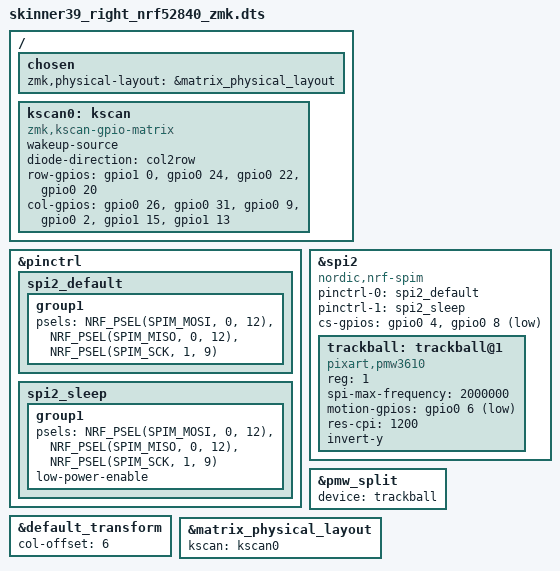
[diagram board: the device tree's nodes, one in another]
#include "skinner39.dtsi"
#include <dt-bindings/led/led.h>
#include <zephyr/dt-bindings/input/input-event-codes.h>

&pinctrl {
    spi2_default: spi2_default {
		group1 {
				psels = <NRF_PSEL(SPIM_MOSI, 0, 12)>,
				<NRF_PSEL(SPIM_MISO, 0, 12)>,
				<NRF_PSEL(SPIM_SCK, 1, 9)>;
		};
	};

    spi2_sleep: spi2_sleep {
		group1 {
				psels = <NRF_PSEL(SPIM_MOSI, 0, 12)>,
				<NRF_PSEL(SPIM_MISO, 0, 12)>,
				<NRF_PSEL(SPIM_SCK, 1, 9)>;
				low-power-enable;
		};
	};
};

nice_view_spi: &spi2 {
    compatible = "nordic,nrf-spim";
    pinctrl-0 = <&spi2_default>;
    pinctrl-1 = <&spi2_sleep>;
    pinctrl-names = "default", "sleep";
    cs-gpios = <&gpio0 4 (GPIO_ACTIVE_HIGH | GPIO_PULL_DOWN) >,
			<&gpio0 8 GPIO_ACTIVE_LOW>;
	trackball: trackball@1 {
		status = "okay";
		compatible = "pixart,pmw3610";
		reg = <1>;
		spi-max-frequency = <2000000>;
		motion-gpios = <&gpio0 6 (GPIO_ACTIVE_LOW | GPIO_PULL_UP)>;
		res-cpi = <1200>;
		invert-y;
	};
};

&pmw_split {
	device = <&trackball>;
};

&default_transform {
	col-offset = <6>;
};

&matrix_physical_layout {
  	kscan = <&kscan0>;
};

/ {
	chosen {
		zmk,physical-layout = &matrix_physical_layout;
	};
    kscan0: kscan {
        compatible = "zmk,kscan-gpio-matrix";
        wakeup-source;

        diode-direction = "col2row";
        row-gpios
            = <&gpio1 0 (GPIO_ACTIVE_HIGH | GPIO_PULL_DOWN)>
            , <&gpio0 24 (GPIO_ACTIVE_HIGH | GPIO_PULL_DOWN)>
            , <&gpio0 22 (GPIO_ACTIVE_HIGH | GPIO_PULL_DOWN)>
            , <&gpio0 20 (GPIO_ACTIVE_HIGH | GPIO_PULL_DOWN)>
            ;
		col-gpios
						= <&gpio0 26 (GPIO_ACTIVE_HIGH | GPIO_PULL_DOWN)>
						, <&gpio0 31 (GPIO_ACTIVE_HIGH | GPIO_PULL_DOWN)>
						, <&gpio0 9 (GPIO_ACTIVE_HIGH | GPIO_PULL_DOWN)>
						, <&gpio0 2 (GPIO_ACTIVE_HIGH | GPIO_PULL_DOWN)>
						, <&gpio1 15 (GPIO_ACTIVE_HIGH | GPIO_PULL_DOWN)>
						, <&gpio1 13 (GPIO_ACTIVE_HIGH | GPIO_PULL_DOWN)>;
    };
};
